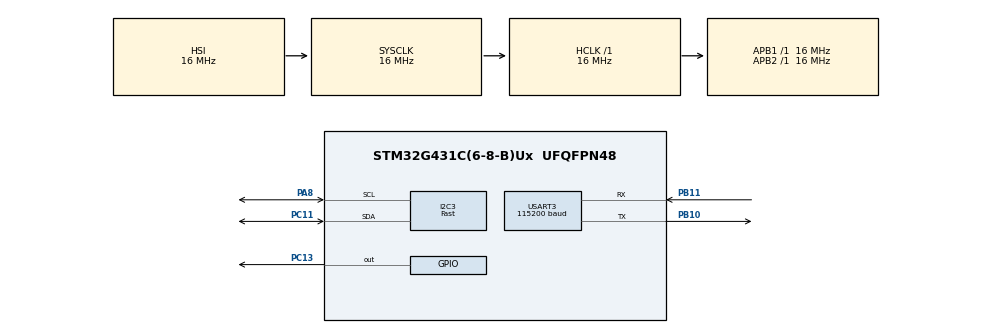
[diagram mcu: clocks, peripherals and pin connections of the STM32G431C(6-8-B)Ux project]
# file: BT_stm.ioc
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ADC1.Channel-0\#ChannelRegularConversion=ADC_CHANNEL_TEMPSENSOR_ADC1
ADC1.ClockPrescaler=ADC_CLOCK_SYNC_PCLK_DIV4
ADC1.ContinuousConvMode=ENABLE
ADC1.DMAContinuousRequests=ENABLE
ADC1.ExternalTrigConv=ADC_SOFTWARE_START
ADC1.ExternalTrigConvEdge=ADC_EXTERNALTRIGCONVEDGE_NONE
ADC1.NbrOfConversion=1
ADC1.NbrOfConversionFlag=1
ADC1.OffsetNumber-0\#ChannelRegularConversion=ADC_OFFSET_NONE
ADC1.Rank-0\#ChannelRegularConversion=1
ADC1.SamplingTime-0\#ChannelRegularConversion=ADC_SAMPLETIME_640CYCLES_5
ADC1.master=1
Dma.ADC1.3.Direction=DMA_PERIPH_TO_MEMORY
Dma.ADC1.3.EventEnable=DISABLE
Dma.ADC1.3.Instance=DMA1_Channel4
Dma.ADC1.3.MemDataAlignment=DMA_MDATAALIGN_HALFWORD
Dma.ADC1.3.MemInc=DMA_MINC_ENABLE
Dma.ADC1.3.Mode=DMA_CIRCULAR
Dma.ADC1.3.PeriphDataAlignment=DMA_PDATAALIGN_HALFWORD
Dma.ADC1.3.PeriphInc=DMA_PINC_DISABLE
Dma.ADC1.3.Polarity=HAL_DMAMUX_REQ_GEN_RISING
Dma.ADC1.3.Priority=DMA_PRIORITY_LOW
Dma.ADC1.3.RequestNumber=1
Dma.ADC1.3.SignalID=NONE
Dma.ADC1.3.SyncEnable=DISABLE
Dma.ADC1.3.SyncPolarity=HAL_DMAMUX_SYNC_NO_EVENT
Dma.ADC1.3.SyncRequestNumber=1
Dma.ADC1.3.SyncSignalID=NONE
Dma.I2C3_TX.2.Direction=DMA_MEMORY_TO_PERIPH
Dma.I2C3_TX.2.EventEnable=DISABLE
Dma.I2C3_TX.2.Instance=DMA1_Channel3
Dma.I2C3_TX.2.MemDataAlignment=DMA_MDATAALIGN_BYTE
Dma.I2C3_TX.2.MemInc=DMA_MINC_ENABLE
Dma.I2C3_TX.2.Mode=DMA_NORMAL
Dma.I2C3_TX.2.PeriphDataAlignment=DMA_PDATAALIGN_BYTE
Dma.I2C3_TX.2.PeriphInc=DMA_PINC_DISABLE
Dma.I2C3_TX.2.Polarity=HAL_DMAMUX_REQ_GEN_RISING
Dma.I2C3_TX.2.Priority=DMA_PRIORITY_LOW
Dma.I2C3_TX.2.RequestNumber=1
Dma.I2C3_TX.2.SignalID=NONE
Dma.I2C3_TX.2.SyncEnable=DISABLE
Dma.I2C3_TX.2.SyncPolarity=HAL_DMAMUX_SYNC_NO_EVENT
Dma.I2C3_TX.2.SyncRequestNumber=1
Dma.I2C3_TX.2.SyncSignalID=NONE
Dma.Request0=USART3_RX
Dma.Request1=USART3_TX
Dma.Request2=I2C3_TX
Dma.Request3=ADC1
Dma.USART3_RX.0.Direction=DMA_PERIPH_TO_MEMORY
Dma.USART3_RX.0.EventEnable=DISABLE
Dma.USART3_RX.0.Instance=DMA1_Channel1
Dma.USART3_RX.0.MemDataAlignment=DMA_MDATAALIGN_BYTE
Dma.USART3_RX.0.MemInc=DMA_MINC_ENABLE
Dma.USART3_RX.0.Mode=DMA_NORMAL
Dma.USART3_RX.0.PeriphDataAlignment=DMA_PDATAALIGN_BYTE
Dma.USART3_RX.0.PeriphInc=DMA_PINC_DISABLE
Dma.USART3_RX.0.Polarity=HAL_DMAMUX_REQ_GEN_RISING
Dma.USART3_RX.0.Priority=DMA_PRIORITY_LOW
Dma.USART3_RX.0.RequestNumber=1
Dma.USART3_RX.0.SignalID=NONE
Dma.USART3_RX.0.SyncEnable=DISABLE
Dma.USART3_RX.0.SyncPolarity=HAL_DMAMUX_SYNC_NO_EVENT
Dma.USART3_RX.0.SyncRequestNumber=1
Dma.USART3_RX.0.SyncSignalID=NONE
Dma.USART3_TX.1.Direction=DMA_MEMORY_TO_PERIPH
Dma.USART3_TX.1.EventEnable=DISABLE
Dma.USART3_TX.1.Instance=DMA1_Channel2
Dma.USART3_TX.1.MemDataAlignment=DMA_MDATAALIGN_BYTE
Dma.USART3_TX.1.MemInc=DMA_MINC_ENABLE
Dma.USART3_TX.1.Mode=DMA_NORMAL
Dma.USART3_TX.1.PeriphDataAlignment=DMA_PDATAALIGN_BYTE
Dma.USART3_TX.1.PeriphInc=DMA_PINC_DISABLE
Dma.USART3_TX.1.Polarity=HAL_DMAMUX_REQ_GEN_RISING
Dma.USART3_TX.1.Priority=DMA_PRIORITY_LOW
Dma.USART3_TX.1.RequestNumber=1
Dma.USART3_TX.1.SignalID=NONE
Dma.USART3_TX.1.SyncEnable=DISABLE
Dma.USART3_TX.1.SyncPolarity=HAL_DMAMUX_SYNC_NO_EVENT
Dma.USART3_TX.1.SyncRequestNumber=1
Dma.USART3_TX.1.SyncSignalID=NONE
I2C3.I2C_Speed_Mode=I2C_Fast
I2C3.OwnAddress=0x78
I2C3.Timing=0x0010061A
Mcu.Family=STM32G4
Mcu.Name=STM32G431C(6-8-B)Ux
Mcu.Package=UFQFPN48
NVIC.ADC1_2_IRQn=true\:0\:0\:false\:false\:true\:true\:true\:true
NVIC.DMA1_Channel1_IRQn=true\:0\:0\:false\:false\:true\:false\:true\:true
NVIC.DMA1_Channel2_IRQn=true\:0\:0\:false\:false\:true\:false\:true\:true
NVIC.DMA1_Channel3_IRQn=true\:0\:0\:false\:false\:true\:false\:true\:true
NVIC.DMA1_Channel4_IRQn=true\:0\:0\:false\:false\:true\:false\:true\:true
NVIC.I2C3_ER_IRQn=true\:0\:0\:false\:false\:true\:true\:true\:true
NVIC.I2C3_EV_IRQn=true\:0\:0\:false\:false\:true\:true\:true\:true
NVIC.PriorityGroup=NVIC_PRIORITYGROUP_4
NVIC.USART3_IRQn=true\:0\:0\:false\:false\:true\:true\:true\:true
PA8.Mode=I2C
PA8.Signal=I2C3_SCL
PB10.Mode=Asynchronous
PB10.Signal=USART3_TX
PB11.Mode=Asynchronous
PB11.Signal=USART3_RX
PC11.Mode=I2C
PC11.Signal=I2C3_SDA
PC13.Signal=GPIO_Output
ProjectManager.HeapSize=0x200
ProjectManager.StackSize=0x400
ProjectManager.TargetToolchain=STM32CubeIDE
RCC.AHBFreq_Value=16000000
RCC.APB1Freq_Value=16000000
RCC.APB1TimFreq_Value=16000000
RCC.APB2Freq_Value=16000000
RCC.APB2TimFreq_Value=16000000
RCC.CortexFreq_Value=16000000
RCC.EXTERNAL_CLOCK_VALUE=12288000
RCC.HCLKFreq_Value=16000000
RCC.HSE_VALUE=8000000
RCC.HSI48_VALUE=48000000
RCC.HSI_VALUE=16000000
RCC.LSE_VALUE=32768
RCC.SYSCLKFreq_VALUE=16000000
RCC.USBFreq_Value=64000000
RCC.VCOOutputFreq_Value=128000000
USART3.BaudRate=115200
USART3.Mode=MODE_TX_RX
USART3.VirtualMode-Asynchronous=VM_ASYNC
VP_ADC1_TempSens_Input.Mode=IN-TempSens
VP_SYS_VS_DBSignals.Mode=DisableDeadBatterySignals
board=custom

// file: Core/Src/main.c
/* USER CODE BEGIN Header */
/**
  ******************************************************************************
  * @file           : main.c
  * @brief          : Main program body
  ******************************************************************************
  * @attention
  *
  * Copyright (c) 2024 STMicroelectronics.
  * All rights reserved.
  *
  * This software is licensed under terms that can be found in the LICENSE file
  * in the root directory of this software component.
  * If no LICENSE file comes with this software, it is provided AS-IS.
  *
  ******************************************************************************
  */
/* USER CODE END Header */
#include "main.h"
#include "adc.h"
#include "dma.h"
#include "i2c.h"
#include "usart.h"
#include "gpio.h"

/* USER CODE BEGIN PV */

// Variáveis para comparação
uint8_t adc[]={0x61,0x61,0x61,0x61,0x61,0x61,0x61,0x61,0x61,0x61,0x61};
uint8_t pwm[]={0x70,0x77,0x6d};
uint8_t on[]={0x6f,0x6e};
uint8_t off[]={0x6f,0x66};

uint8_t tx_buff[]={65,66,67,68,69,70,71,72,73,74}; // Alfabeto

int i,j;

uint32_t AdcRaw;

extern uint8_t rx_buff[10];
/* USER CODE END PV */

void SystemClock_Config(void);

/* USER CODE BEGIN 0 */

void HAL_UART_RxCpltCallback(UART_HandleTypeDef *huart)
{
	  if(huart == &huart3){
		  // trata usart 3
	  }
}

/* USER CODE END 0 */

int main(void)
{

  /* MCU Configuration--------------------------------------------------------*/

  /* Reset of all peripherals, Initializes the Flash interface and the Systick. */
  HAL_Init();

  /* Configure the system clock */
  SystemClock_Config();

  /* Initialize all configured peripherals */
  MX_GPIO_Init();
  MX_DMA_Init();
  MX_USART3_UART_Init();
  MX_I2C3_Init();
  MX_ADC1_Init();
  /* USER CODE BEGIN 2 */

  SSD1306_Init(); // Inicialização da biblioteca do display

  Display_Init(); // Inicialização do demo display (TESTE LCE)

  HAL_ADC_Start_DMA(&hadc1, &AdcRaw, 1);

  /* USER CODE END 2 */

  /* Infinite loop */
  while (1)
  {

    /* USER CODE BEGIN 3 */
	teste(); // Demo de teste com valor float

  }
  /* USER CODE END 3 */
}

void SystemClock_Config(void)
{
  RCC_OscInitTypeDef RCC_OscInitStruct = {0};
  RCC_ClkInitTypeDef RCC_ClkInitStruct = {0};

  /** Configure the main internal regulator output voltage
  */
  HAL_PWREx_ControlVoltageScaling(PWR_REGULATOR_VOLTAGE_SCALE1);

  /** Initializes the RCC Oscillators according to the specified parameters
  * in the RCC_OscInitTypeDef structure.
  */
  RCC_OscInitStruct.OscillatorType = RCC_OSCILLATORTYPE_HSI;
  RCC_OscInitStruct.HSIState = RCC_HSI_ON;
  RCC_OscInitStruct.HSICalibrationValue = RCC_HSICALIBRATION_DEFAULT;
  RCC_OscInitStruct.PLL.PLLState = RCC_PLL_NONE;
  if (HAL_RCC_OscConfig(&RCC_OscInitStruct) != HAL_OK)
  {
    Error_Handler();
  }

  /** Initializes the CPU, AHB and APB buses clocks
  */
  RCC_ClkInitStruct.ClockType = RCC_CLOCKTYPE_HCLK|RCC_CLOCKTYPE_SYSCLK
                              |RCC_CLOCKTYPE_PCLK1|RCC_CLOCKTYPE_PCLK2;
  RCC_ClkInitStruct.SYSCLKSource = RCC_SYSCLKSOURCE_HSI;
  RCC_ClkInitStruct.AHBCLKDivider = RCC_SYSCLK_DIV1;
  RCC_ClkInitStruct.APB1CLKDivider = RCC_HCLK_DIV1;
  RCC_ClkInitStruct.APB2CLKDivider = RCC_HCLK_DIV1;

  if (HAL_RCC_ClockConfig(&RCC_ClkInitStruct, FLASH_LATENCY_0) != HAL_OK)
  {
    Error_Handler();
  }
}

/* USER CODE BEGIN 4 */

// Conversão de ascii para char

/* USER CODE END 4 */

void Error_Handler(void)
{
  __disable_irq();
  while (1)
  {
  }
}
